VERSION "Emergency_System_CAN_Body_v1.3"

NS_ :

BS_:

BU_: BODY_GW BCM_AMBIENT_CTRL WARN_ARB_MGR HAZARD_CTRL WINDOW_CTRL DRIVER_STATE_CTRL Vector__XXX

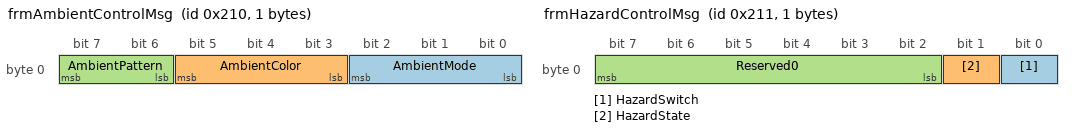
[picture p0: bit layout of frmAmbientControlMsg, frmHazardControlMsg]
BO_ 528 frmAmbientControlMsg: 1 BODY_GW
 SG_ AmbientMode      : 0|3@1+ (1,0) [0|7] "" BCM_AMBIENT_CTRL
 SG_ AmbientColor     : 3|3@1+ (1,0) [0|7] "" BCM_AMBIENT_CTRL
 SG_ AmbientPattern   : 6|2@1+ (1,0) [0|3] "" BCM_AMBIENT_CTRL

BO_ 529 frmHazardControlMsg: 1 BODY_GW
 SG_ HazardSwitch     : 0|1@1+ (1,0) [0|1] "" HAZARD_CTRL
 SG_ HazardState      : 1|1@1+ (1,0) [0|1] "" HAZARD_CTRL
 SG_ Reserved0        : 2|6@1+ (1,0) [0|0] "" Vector__XXX

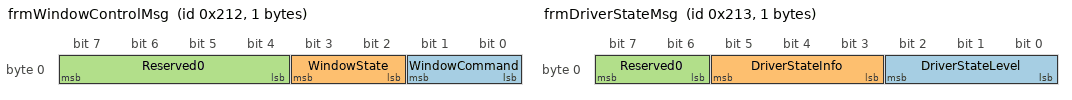
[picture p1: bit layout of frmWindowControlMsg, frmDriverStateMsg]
BO_ 530 frmWindowControlMsg: 1 BODY_GW
 SG_ WindowCommand    : 0|2@1+ (1,0) [0|3] "" WINDOW_CTRL
 SG_ WindowState      : 2|2@1+ (1,0) [0|3] "" WINDOW_CTRL
 SG_ Reserved0        : 4|4@1+ (1,0) [0|0] "" Vector__XXX

BO_ 531 frmDriverStateMsg: 1 BODY_GW
 SG_ DriverStateLevel : 0|3@1+ (1,0) [0|7] "" DRIVER_STATE_CTRL
 SG_ DriverStateInfo  : 3|3@1+ (1,0) [0|7] "" DRIVER_STATE_CTRL
 SG_ Reserved0        : 6|2@1+ (1,0) [0|0] "" Vector__XXX

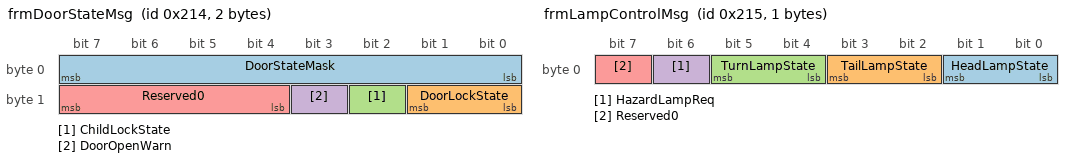
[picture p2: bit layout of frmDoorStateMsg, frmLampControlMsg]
BO_ 532 frmDoorStateMsg: 2 BODY_GW
 SG_ DoorStateMask    : 0|8@1+ (1,0) [0|255] "" WINDOW_CTRL,DRIVER_STATE_CTRL
 SG_ DoorLockState    : 8|2@1+ (1,0) [0|3] "" WINDOW_CTRL,DRIVER_STATE_CTRL
 SG_ ChildLockState   : 10|1@1+ (1,0) [0|1] "" WINDOW_CTRL,DRIVER_STATE_CTRL
 SG_ DoorOpenWarn     : 11|1@1+ (1,0) [0|1] "" WINDOW_CTRL,DRIVER_STATE_CTRL
 SG_ Reserved0        : 12|4@1+ (1,0) [0|0] "" Vector__XXX

BO_ 533 frmLampControlMsg: 1 BODY_GW
 SG_ HeadLampState    : 0|2@1+ (1,0) [0|3] "" BCM_AMBIENT_CTRL
 SG_ TailLampState    : 2|2@1+ (1,0) [0|3] "" BCM_AMBIENT_CTRL
 SG_ TurnLampState    : 4|2@1+ (1,0) [0|3] "" BCM_AMBIENT_CTRL
 SG_ HazardLampReq    : 6|1@1+ (1,0) [0|1] "" HAZARD_CTRL
 SG_ Reserved0        : 7|1@1+ (1,0) [0|0] "" Vector__XXX

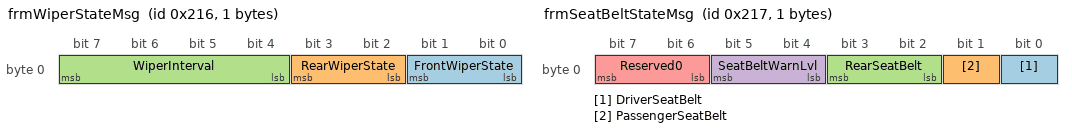
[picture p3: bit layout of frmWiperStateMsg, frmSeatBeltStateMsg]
BO_ 534 frmWiperStateMsg: 1 BODY_GW
 SG_ FrontWiperState  : 0|2@1+ (1,0) [0|3] "" BCM_AMBIENT_CTRL
 SG_ RearWiperState   : 2|2@1+ (1,0) [0|3] "" BCM_AMBIENT_CTRL
 SG_ WiperInterval    : 4|4@1+ (1,0) [0|15] "" BCM_AMBIENT_CTRL

BO_ 535 frmSeatBeltStateMsg: 1 DRIVER_STATE_CTRL
 SG_ DriverSeatBelt   : 0|1@1+ (1,0) [0|1] "" BODY_GW,BCM_AMBIENT_CTRL
 SG_ PassengerSeatBelt : 1|1@1+ (1,0) [0|1] "" BODY_GW,BCM_AMBIENT_CTRL
 SG_ RearSeatBelt     : 2|2@1+ (1,0) [0|3] "" BODY_GW,BCM_AMBIENT_CTRL
 SG_ SeatBeltWarnLvl  : 4|2@1+ (1,0) [0|3] "" BODY_GW,BCM_AMBIENT_CTRL
 SG_ Reserved0        : 6|2@1+ (1,0) [0|0] "" Vector__XXX

BO_ 536 frmCabinAirStateMsg: 2 DRIVER_STATE_CTRL
 SG_ CabinTemp        : 0|8@1+ (1,0) [0|100] "degC" BODY_GW
 SG_ AirQualityIndex  : 8|8@1+ (1,0) [0|255] "" BODY_GW

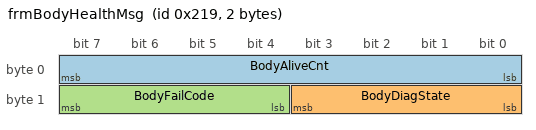
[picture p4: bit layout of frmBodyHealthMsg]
BO_ 537 frmBodyHealthMsg: 2 BODY_GW
 SG_ BodyAliveCnt     : 0|8@1+ (1,0) [0|255] "" SIL_TEST_CTRL
 SG_ BodyDiagState    : 8|4@1+ (1,0) [0|15] "" SIL_TEST_CTRL
 SG_ BodyFailCode     : 12|4@1+ (1,0) [0|15] "" SIL_TEST_CTRL

CM_ BU_ BODY_GW          "Gateway: selected alert to Body CAN (0x210).";
CM_ BU_ BCM_AMBIENT_CTRL "Ambient controller ECU (consumer of 0x210).";
CM_ BU_ WARN_ARB_MGR     "Central arbitration manager (upstream logic owner).";
CM_ BU_ HAZARD_CTRL      "Vehicle baseline node for hazard switch handling (Req_106).";
CM_ BU_ WINDOW_CTRL      "Vehicle baseline node for window state handling (Req_107).";
CM_ BU_ DRIVER_STATE_CTRL "Vehicle baseline node for driver-state forwarding (Req_108).";
CM_ BU_ Vector__XXX      "Reserved node for unused or filler signals.";

CM_ BO_ 528 "Body CAN output: ambient mode/color/pattern.";
CM_ BO_ 529 "Body baseline: hazard switch and hazard state.";
CM_ BO_ 530 "Body baseline: window command and window state.";
CM_ BO_ 531 "Body baseline: driver state level and state info.";
CM_ BO_ 532 "Body baseline: door mask/lock/child-lock/open-warning state.";
CM_ BO_ 533 "Body baseline: lamp and hazard request state.";
CM_ BO_ 534 "Body baseline: front/rear wiper state and interval.";
CM_ BO_ 535 "Body baseline: seat-belt occupancy and warning level.";
CM_ BO_ 536 "Body baseline: cabin temperature and air quality index.";
CM_ BO_ 537 "Body health/diagnostic state.";

CM_ "Domain split: body CAN network from emergency_system.dbc baseline.";
CM_ "Post-mentoring alignment: body domain includes baseline hazard/window/driver-state nodes.";

BA_DEF_ BO_ "GenMsgCycleTime" INT 0 10000;
BA_DEF_DEF_ "GenMsgCycleTime" 0;

BA_ "GenMsgCycleTime" BO_ 528 50;
BA_ "GenMsgCycleTime" BO_ 529 100;
BA_ "GenMsgCycleTime" BO_ 530 100;
BA_ "GenMsgCycleTime" BO_ 531 100;
BA_ "GenMsgCycleTime" BO_ 532 100;
BA_ "GenMsgCycleTime" BO_ 533 100;
BA_ "GenMsgCycleTime" BO_ 534 100;
BA_ "GenMsgCycleTime" BO_ 535 100;
BA_ "GenMsgCycleTime" BO_ 536 100;
BA_ "GenMsgCycleTime" BO_ 537 100;

  0 "Off"
  1 "Basic"
  2 "Caution"
  3 "SchoolZone"
  4 "Reserved"
  5 "GuideLeft"
  6 "GuideRight"
  7 "Emergency" ;

  0 "None"
  1 "DefaultBlink"
  2 "GuideLeftPattern"
  3 "GuideRightPattern" ;

  0 "Off"
  1 "On" ;

  0 "Inactive"
  1 "Active" ;

  0 "NoCmd"
  1 "Open"
  2 "Close"
  3 "Stop" ;

  0 "Unknown"
  1 "Opened"
  2 "Closed"
  3 "Moving" ;

  0 "Normal"
  1 "MildDrowsy"
  2 "Drowsy"
  3 "Distracted"
  4 "Critical"
  5 "Reserved5"
  6 "Reserved6"
  7 "Reserved7" ;

  0 "Unlocked"
  1 "Locked"
  2 "AutoLock"
  3 "Fault" ;

  0 "Off"
  1 "On" ;

  0 "NoWarn"
  1 "Warn" ;

  0 "Off"
  1 "Parking"
  2 "LowBeam"
  3 "HighBeam" ;

  0 "Off"
  1 "On"
  2 "Auto"
  3 "Fault" ;

  0 "Off"
  1 "Left"
  2 "Right"
  3 "Hazard" ;

  0 "Off"
  1 "On" ;

  0 "Off"
  1 "Low"
  2 "High"
  3 "Auto" ;

  0 "Off"
  1 "On"
  2 "Intermittent"
  3 "Fault" ;

  0 "Unbuckled"
  1 "Buckled" ;

  0 "Unbuckled"
  1 "Buckled" ;

  0 "None"
  1 "SomeUnbuckled"
  2 "AllBuckled"
  3 "Fault" ;

  0 "None"
  1 "Info"
  2 "Warn"
  3 "Critical" ;
